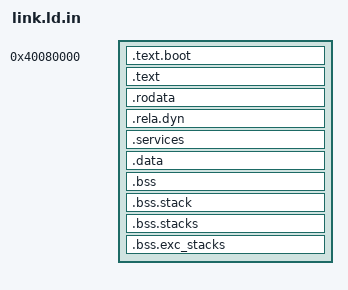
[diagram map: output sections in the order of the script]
/*
 * Kernel linker script (generated from link.ld.in by build.rs).
 * Values substituted from system_config.rs — do not hardcode here.
 *
 * AUDIT: 2026-03-11 — see git history for original audit notes.
 */

ENTRY(_start)

KERNEL_VA_OFFSET = @KERNEL_VA_OFFSET_HEX@;
PHYS_BASE        = 0x40080000;

SECTIONS
{
  /*
   * .text.boot runs at physical VA before TTBR1 is live.
   * VMA = LMA = physical address.
   */
  . = PHYS_BASE;

  __text_boot_start = .;
  .text.boot : {
    KEEP(*(.text.boot))
  }
  __text_boot_end = .;

  /*
   * Everything below runs at upper VA (TTBR1).
   * VMA = PA + KERNEL_VA_OFFSET.  LMA = PA (via AT()).
   */
  . = ALIGN(@PAGE_SIZE@) + KERNEL_VA_OFFSET;

  /* --- Executable, read-only (RX) --- */
  __text_start = .;
  .text : AT(ADDR(.text) - KERNEL_VA_OFFSET) ALIGN(16) {
    *(.text .text.*)
  }
  __text_end = .;

  /* --- Read-only, no execute (RO) --- */
  . = ALIGN(@PAGE_SIZE@);
  __rodata_start = .;
  .rodata : AT(ADDR(.rodata) - KERNEL_VA_OFFSET) {
    *(.rodata .rodata.*)
  }

  /* --- KASLR relocations (PIE, allocated .rela.dyn) ---
   *
   * With --pie, the linker generates R_AARCH64_RELATIVE entries in an
   * allocated .rela.dyn section (SHF_ALLOC). boot.S iterates these at
   * physical addresses before MMU enable, adding the KASLR slide to each
   * absolute kernel VA. Self-contained: no post-link tool needed.
   */
  __rela_start = .;
  .rela.dyn : AT(ADDR(.rela.dyn) - KERNEL_VA_OFFSET) {
    *(.rela.dyn .rela.dyn.*)
  }
  __rela_end = .;
  __rodata_end = .;

  /* --- Service pack (RO, page-aligned) --- */
  . = ALIGN(@PAGE_SIZE@);
  _services_start = .;
  .services : AT(ADDR(.services) - KERNEL_VA_OFFSET) {
    KEEP(*(.services))
  }
  _services_end = .;

  /* --- Read-write, no execute (RW) --- */
  . = ALIGN(@PAGE_SIZE@);
  __data_start = .;
  .data : AT(ADDR(.data) - KERNEL_VA_OFFSET) {
    *(.data .data.*)
  }
  .bss : AT(ADDR(.bss) - KERNEL_VA_OFFSET) ALIGN(16) {
    __bss_start = .;
    *(.bss .bss.*)
    *(COMMON)
    __bss_end = .;
  }
  . = ALIGN(16);
  .bss.stack (NOLOAD) : AT(ADDR(.bss.stack) - KERNEL_VA_OFFSET) ALIGN(16) {
    __stack_bottom = .;
    . = . + 0x10000; /* 64 KiB primary kernel stack */
    __stack_top = .;
  }

  /* Secondary core kernel stacks: 7 cores x @PAGE_SIZE@ bytes each.
   * Core N (1..7) uses __secondary_stacks + N * @PAGE_SIZE_HEX@ as its stack top. */
  .bss.stacks (NOLOAD) : AT(ADDR(.bss.stacks) - KERNEL_VA_OFFSET) ALIGN(16) {
    __secondary_stacks = .;
    . = . + (7 * @PAGE_SIZE_HEX@);
    __secondary_stacks_end = .;
  }

  /* Per-core emergency exception stacks (@PAGE_SIZE@ x MAX_CORES, page-aligned).
   * Used by exc_fatal when the original SP is corrupted (guard page hit). */
  .bss.exc_stacks (NOLOAD) : AT(ADDR(.bss.exc_stacks) - KERNEL_VA_OFFSET) ALIGN(@PAGE_SIZE@) {
    *(.bss.exc_stacks)
  }

  /* Physical companions for boot code (which runs before TTBR1 is live). */
  __bss_start_phys  = __bss_start  - KERNEL_VA_OFFSET;
  __bss_end_phys    = __bss_end    - KERNEL_VA_OFFSET;
  __stack_top_phys  = __stack_top  - KERNEL_VA_OFFSET;
  boot_tt0_l2_phys  = boot_tt0_l2 - KERNEL_VA_OFFSET;
  boot_tt1_l2_phys  = boot_tt1_l2 - KERNEL_VA_OFFSET;
  __rela_start_phys = __rela_start - KERNEL_VA_OFFSET;
  __rela_end_phys   = __rela_end   - KERNEL_VA_OFFSET;

  . = ALIGN(@PAGE_SIZE@);
  __kernel_end = .;
}
